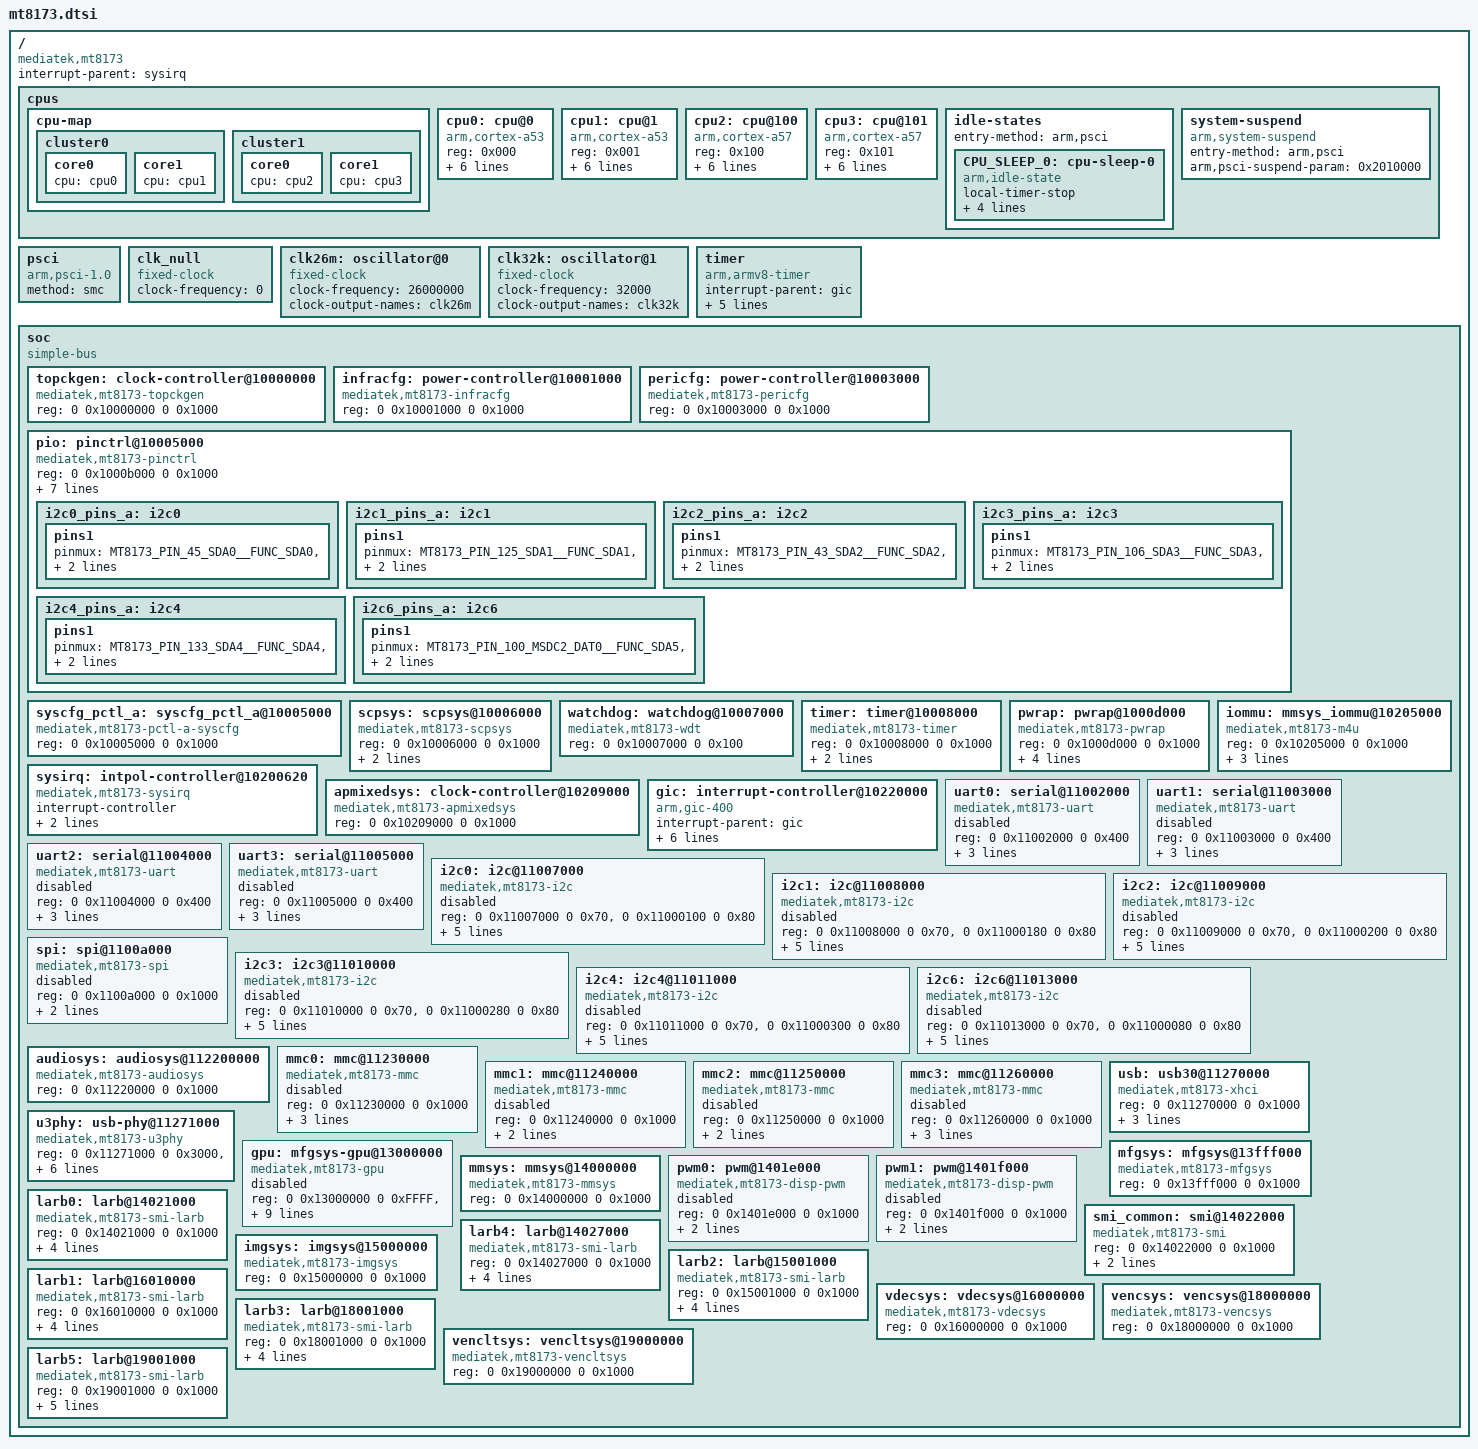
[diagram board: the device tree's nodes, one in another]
/*
 * Copyright (c) 2014 MediaTek Inc.
 * Author: Eddie Huang <eddie.huang@mediatek.com>
 *
 * This program is free software; you can redistribute it and/or modify
 * it under the terms of the GNU General Public License version 2 as
 * published by the Free Software Foundation.
 *
 * This program is distributed in the hope that it will be useful,
 * MERCHANTABILITY or FITNESS FOR A PARTICULAR PURPOSE.  See the
 * GNU General Public License for more details.
 */

#include <dt-bindings/clock/mt8173-clk.h>
#include <dt-bindings/interrupt-controller/irq.h>
#include <dt-bindings/interrupt-controller/arm-gic.h>
#include <dt-bindings/power/mt8173-power.h>
#include <dt-bindings/reset-controller/mt8173-resets.h>
#include <dt-bindings/iommu/mt8173-iommu-port.h>
#include "mt8173-pinfunc.h"

/ {
	compatible = "mediatek,mt8173";
	interrupt-parent = <&sysirq>;
	#address-cells = <2>;
	#size-cells = <2>;

	cpus {
		#address-cells = <1>;
		#size-cells = <0>;

		cpu-map {
			cluster0 {
				core0 {
					cpu = <&cpu0>;
				};
				core1 {
					cpu = <&cpu1>;
				};
			};

			cluster1 {
				core0 {
					cpu = <&cpu2>;
				};
				core1 {
					cpu = <&cpu3>;
				};
			};
		};

		cpu0: cpu@0 {
			device_type = "cpu";
			compatible = "arm,cortex-a53";
			reg = <0x000>;
			clocks = <&infracfg CLK_INFRA_CA53SEL>,
				 <&apmixedsys CLK_APMIXED_MAINPLL>;
			clock-names = "cpu", "intermediate";
			operating-points = <
				507000  859000
				702000  908000
				1001000 983000
				1105000 1009000
				1183000 1028000
				1404000 1083000
				1508000 1109000
				1573000 1125000
			>;
			enable-method = "psci";
			cpu-idle-states = <&CPU_SLEEP_0>;
		};

		cpu1: cpu@1 {
			device_type = "cpu";
			compatible = "arm,cortex-a53";
			reg = <0x001>;
			enable-method = "psci";
			clocks = <&infracfg CLK_INFRA_CA53SEL>,
				 <&apmixedsys CLK_APMIXED_MAINPLL>;
			clock-names = "cpu", "intermediate";
			operating-points = <
				507000  859000
				702000  908000
				1001000 983000
				1105000 1009000
				1183000 1028000
				1404000 1083000
				1508000 1109000
				1573000 1125000
			>;
			cpu-idle-states = <&CPU_SLEEP_0>;
		};

		cpu2: cpu@100 {
			device_type = "cpu";
			compatible = "arm,cortex-a57";
			reg = <0x100>;
			enable-method = "psci";
			clocks = <&infracfg CLK_INFRA_CA57SEL>,
				 <&apmixedsys CLK_APMIXED_MAINPLL>;
			clock-names = "cpu", "intermediate";
			operating-points = <
				507000  828000
				702000  867000
				1001000 927000
				1209000 968000
				1404000 1007000
				1612000 1049000
				1807000 1089000
				1989000 1125000
			>;
			cpu-idle-states = <&CPU_SLEEP_0>;
		};

		cpu3: cpu@101 {
			device_type = "cpu";
			compatible = "arm,cortex-a57";
			reg = <0x101>;
			enable-method = "psci";
			clocks = <&infracfg CLK_INFRA_CA57SEL>,
				 <&apmixedsys CLK_APMIXED_MAINPLL>;
			clock-names = "cpu", "intermediate";
			operating-points = <
				507000  828000
				702000  867000
				1001000 927000
				1209000 968000
				1404000 1007000
				1612000 1049000
				1807000 1089000
				1989000 1125000
			>;
			cpu-idle-states = <&CPU_SLEEP_0>;
		};

		idle-states {
			entry-method = "arm,psci";

			CPU_SLEEP_0: cpu-sleep-0 {
				compatible = "arm,idle-state";
				local-timer-stop;
				entry-latency-us = <639>;
				exit-latency-us = <680>;
				min-residency-us = <1088>;
				arm,psci-suspend-param = <0x0010000>;
			};
		};

		system-suspend {
			compatible = "arm,system-suspend";
			entry-method = "arm,psci";
			arm,psci-suspend-param = <0x2010000>;
		};


	};

	psci {
		compatible = "arm,psci-1.0";
		method = "smc";
	};

	clk_null: clk_null {
		compatible = "fixed-clock";
		clock-frequency = <0>;
		#clock-cells = <0>;
	};

	clk26m: oscillator@0 {
		compatible = "fixed-clock";
		#clock-cells = <0>;
		clock-frequency = <26000000>;
		clock-output-names = "clk26m";
	};

	clk32k: oscillator@1 {
		compatible = "fixed-clock";
		#clock-cells = <0>;
		clock-frequency = <32000>;
		clock-output-names = "clk32k";
	};

	timer {
		compatible = "arm,armv8-timer";
		interrupt-parent = <&gic>;
		interrupts = <GIC_PPI 13
			      (GIC_CPU_MASK_SIMPLE(4) | IRQ_TYPE_LEVEL_LOW)>,
			     <GIC_PPI 14
			      (GIC_CPU_MASK_SIMPLE(4) | IRQ_TYPE_LEVEL_LOW)>,
			     <GIC_PPI 11
			      (GIC_CPU_MASK_SIMPLE(4) | IRQ_TYPE_LEVEL_LOW)>,
			     <GIC_PPI 10
			      (GIC_CPU_MASK_SIMPLE(4) | IRQ_TYPE_LEVEL_LOW)>;
	};

	soc {
		#address-cells = <2>;
		#size-cells = <2>;
		compatible = "simple-bus";
		ranges;

		topckgen: clock-controller@10000000 {
			compatible = "mediatek,mt8173-topckgen";
			reg = <0 0x10000000 0 0x1000>;
			#clock-cells = <1>;
		};

		infracfg: power-controller@10001000 {
			compatible = "mediatek,mt8173-infracfg", "syscon";
			reg = <0 0x10001000 0 0x1000>;
			#clock-cells = <1>;
			#reset-cells = <1>;
		};

		pericfg: power-controller@10003000 {
			compatible = "mediatek,mt8173-pericfg", "syscon";
			reg = <0 0x10003000 0 0x1000>;
			#clock-cells = <1>;
			#reset-cells = <1>;
		};

		/*
		 * Pinctrl access register at 0x10005000 through regmap.
		 * Register 0x1000b000 is used by EINT.
		 */
		pio: pinctrl@10005000 {
			compatible = "mediatek,mt8173-pinctrl";
			reg = <0 0x1000b000 0 0x1000>;
			mediatek,pctl-regmap = <&syscfg_pctl_a>;
			pins-are-numbered;
			gpio-controller;
			#gpio-cells = <2>;
			interrupt-controller;
			#interrupt-cells = <2>;
			interrupts = <GIC_SPI 145 IRQ_TYPE_LEVEL_HIGH>,
				     <GIC_SPI 146 IRQ_TYPE_LEVEL_HIGH>,
				     <GIC_SPI 147 IRQ_TYPE_LEVEL_HIGH>;

			i2c0_pins_a: i2c0 {
				pins1 {
					pinmux = <MT8173_PIN_45_SDA0__FUNC_SDA0>,
						 <MT8173_PIN_46_SCL0__FUNC_SCL0>;
					bias-disable;
				};
			};

			i2c1_pins_a: i2c1 {
				pins1 {
					pinmux = <MT8173_PIN_125_SDA1__FUNC_SDA1>,
						 <MT8173_PIN_126_SCL1__FUNC_SCL1>;
					bias-disable;
				};
			};

			i2c2_pins_a: i2c2 {
				pins1 {
					pinmux = <MT8173_PIN_43_SDA2__FUNC_SDA2>,
						 <MT8173_PIN_44_SCL2__FUNC_SCL2>;
					bias-disable;
				};
			};

			i2c3_pins_a: i2c3 {
				pins1 {
					pinmux = <MT8173_PIN_106_SDA3__FUNC_SDA3>,
						 <MT8173_PIN_107_SCL3__FUNC_SCL3>;
					bias-disable;
				};
			};

			i2c4_pins_a: i2c4 {
				pins1 {
					pinmux = <MT8173_PIN_133_SDA4__FUNC_SDA4>,
						 <MT8173_PIN_134_SCL4__FUNC_SCL4>;
					bias-disable;
				};
			};

			i2c6_pins_a: i2c6 {
				pins1 {
					pinmux = <MT8173_PIN_100_MSDC2_DAT0__FUNC_SDA5>,
						 <MT8173_PIN_101_MSDC2_DAT1__FUNC_SCL5>;
					bias-disable;
				};
			};
		};

		syscfg_pctl_a: syscfg_pctl_a@10005000 {
			compatible = "mediatek,mt8173-pctl-a-syscfg", "syscon";
			reg = <0 0x10005000 0 0x1000>;
		};

		scpsys: scpsys@10006000 {
			compatible = "mediatek,mt8173-scpsys";
			#power-domain-cells = <1>;
			reg = <0 0x10006000 0 0x1000>;
			clocks = <&clk26m>,
				 <&topckgen CLK_TOP_MM_SEL>;
			clock-names = "mfg", "mm";
			infracfg = <&infracfg>;
		};

		watchdog: watchdog@10007000 {
			compatible = "mediatek,mt8173-wdt",
				     "mediatek,mt6589-wdt";
			reg = <0 0x10007000 0 0x100>;
		};

		timer: timer@10008000 {
			compatible = "mediatek,mt8173-timer",
				     "mediatek,mt6577-timer";
			reg = <0 0x10008000 0 0x1000>;
			interrupts = <GIC_SPI 144 IRQ_TYPE_LEVEL_LOW>;
			clock-frequency = <13000000>;
		};

		pwrap: pwrap@1000d000 {
			compatible = "mediatek,mt8173-pwrap";
			reg = <0 0x1000d000 0 0x1000>;
			reg-names = "pwrap";
			interrupts = <GIC_SPI 153 IRQ_TYPE_LEVEL_HIGH>;
			resets = <&infracfg MT8173_INFRA_PMIC_WRAP_RST>;
			reset-names = "pwrap";
			clocks = <&infracfg CLK_INFRA_PMICSPI>, <&infracfg CLK_INFRA_PMICWRAP>;
			clock-names = "spi", "wrap";
		};

		sysirq: intpol-controller@10200620 {
			compatible = "mediatek,mt8173-sysirq",
				     "mediatek,mt6577-sysirq";
			interrupt-controller;
			#interrupt-cells = <3>;
			interrupt-parent = <&gic>;
			reg = <0 0x10200620 0 0x20>;
		};

		iommu: mmsys_iommu@10205000 {
			compatible = "mediatek,mt8173-m4u";
			reg = <0 0x10205000 0 0x1000>;
			interrupts = <GIC_SPI 139 IRQ_TYPE_LEVEL_LOW>;
			clocks = <&infracfg CLK_INFRA_M4U>;
			clock-names = "bclk";
			larb = <&larb0 &larb1 &larb2 &larb3 &larb4 &larb5>;
			#iommu-cells = <2>;
		};

		apmixedsys: clock-controller@10209000 {
			compatible = "mediatek,mt8173-apmixedsys";
			reg = <0 0x10209000 0 0x1000>;
			#clock-cells = <1>;
		};

		gic: interrupt-controller@10220000 {
			compatible = "arm,gic-400";
			#interrupt-cells = <3>;
			interrupt-parent = <&gic>;
			interrupt-controller;
			reg = <0 0x10221000 0 0x1000>,
			      <0 0x10222000 0 0x2000>,
			      <0 0x10224000 0 0x2000>,
			      <0 0x10226000 0 0x2000>;
			interrupts = <GIC_PPI 9
				(GIC_CPU_MASK_SIMPLE(4) | IRQ_TYPE_LEVEL_HIGH)>;
		};

		uart0: serial@11002000 {
			compatible = "mediatek,mt8173-uart",
				     "mediatek,mt6577-uart";
			reg = <0 0x11002000 0 0x400>;
			interrupts = <GIC_SPI 83 IRQ_TYPE_LEVEL_LOW>;
			clocks = <&pericfg CLK_PERI_UART0_SEL>, <&pericfg CLK_PERI_UART0>;
			clock-names = "baud", "bus";
			status = "disabled";
		};

		uart1: serial@11003000 {
			compatible = "mediatek,mt8173-uart",
				     "mediatek,mt6577-uart";
			reg = <0 0x11003000 0 0x400>;
			interrupts = <GIC_SPI 84 IRQ_TYPE_LEVEL_LOW>;
			clocks = <&pericfg CLK_PERI_UART1_SEL>, <&pericfg CLK_PERI_UART1>;
			clock-names = "baud", "bus";
			status = "disabled";
		};

		uart2: serial@11004000 {
			compatible = "mediatek,mt8173-uart",
				     "mediatek,mt6577-uart";
			reg = <0 0x11004000 0 0x400>;
			interrupts = <GIC_SPI 85 IRQ_TYPE_LEVEL_LOW>;
			clocks = <&pericfg CLK_PERI_UART2_SEL>, <&pericfg CLK_PERI_UART2>;
			clock-names = "baud", "bus";
			status = "disabled";
		};

		uart3: serial@11005000 {
			compatible = "mediatek,mt8173-uart",
				     "mediatek,mt6577-uart";
			reg = <0 0x11005000 0 0x400>;
			interrupts = <GIC_SPI 86 IRQ_TYPE_LEVEL_LOW>;
			clocks = <&pericfg CLK_PERI_UART3_SEL>, <&pericfg CLK_PERI_UART3>;
			clock-names = "baud", "bus";
			status = "disabled";
		};

		i2c0: i2c@11007000 {
			compatible = "mediatek,mt8173-i2c";
			reg = <0 0x11007000 0 0x70>,
			      <0 0x11000100 0 0x80>;
			interrupts = <GIC_SPI 76 IRQ_TYPE_LEVEL_LOW>;
			clock-div = <16>;
			clocks = <&pericfg CLK_PERI_I2C0>,
				 <&pericfg CLK_PERI_AP_DMA>;
			clock-names = "main", "dma";
			pinctrl-names = "default";
			pinctrl-0 = <&i2c0_pins_a>;
			#address-cells = <1>;
			#size-cells = <0>;
			status = "disabled";
		};

		i2c1: i2c@11008000 {
			compatible = "mediatek,mt8173-i2c";
			reg = <0 0x11008000 0 0x70>,
			      <0 0x11000180 0 0x80>;
			interrupts = <GIC_SPI 77 IRQ_TYPE_LEVEL_LOW>;
			clock-div = <16>;
			clocks = <&pericfg CLK_PERI_I2C1>,
				 <&pericfg CLK_PERI_AP_DMA>;
			clock-names = "main", "dma";
			pinctrl-names = "default";
			pinctrl-0 = <&i2c1_pins_a>;
			#address-cells = <1>;
			#size-cells = <0>;
			status = "disabled";
		};

		i2c2: i2c@11009000 {
			compatible = "mediatek,mt8173-i2c";
			reg = <0 0x11009000 0 0x70>,
			      <0 0x11000200 0 0x80>;
			interrupts = <GIC_SPI 78 IRQ_TYPE_LEVEL_LOW>;
			clock-div = <16>;
			clocks = <&pericfg CLK_PERI_I2C2>,
				 <&pericfg CLK_PERI_AP_DMA>;
			clock-names = "main", "dma";
			pinctrl-names = "default";
			pinctrl-0 = <&i2c2_pins_a>;
			#address-cells = <1>;
			#size-cells = <0>;
			status = "disabled";
		};

		spi: spi@1100a000 {
			compatible = "mediatek,mt8173-spi";
			reg = <0 0x1100a000 0 0x1000>;
			interrupts = <GIC_SPI 110 IRQ_TYPE_LEVEL_LOW>;
			clocks = <&pericfg CLK_PERI_SPI0>;
			clock-names = "main";
			status = "disabled";
		};

		i2c3: i2c3@11010000 {
			compatible = "mediatek,mt8173-i2c";
			reg = <0 0x11010000 0 0x70>,
			      <0 0x11000280 0 0x80>;
			interrupts = <GIC_SPI 79 IRQ_TYPE_LEVEL_LOW>;
			clock-div = <16>;
			clocks = <&pericfg CLK_PERI_I2C3>,
				 <&pericfg CLK_PERI_AP_DMA>;
			clock-names = "main", "dma";
			pinctrl-names = "default";
			pinctrl-0 = <&i2c3_pins_a>;
			#address-cells = <1>;
			#size-cells = <0>;
			status = "disabled";
		};

		i2c4: i2c4@11011000 {
			compatible = "mediatek,mt8173-i2c";
			reg = <0 0x11011000 0 0x70>,
			      <0 0x11000300 0 0x80>;
			interrupts = <GIC_SPI 80 IRQ_TYPE_LEVEL_LOW>;
			clock-div = <16>;
			clocks = <&pericfg CLK_PERI_I2C4>,
				 <&pericfg CLK_PERI_AP_DMA>;
			clock-names = "main", "dma";
			pinctrl-names = "default";
			pinctrl-0 = <&i2c4_pins_a>;
			#address-cells = <1>;
			#size-cells = <0>;
			status = "disabled";
		};

		i2c6: i2c6@11013000 {
			compatible = "mediatek,mt8173-i2c";
			reg = <0 0x11013000 0 0x70>,
			      <0 0x11000080 0 0x80>;
			interrupts = <GIC_SPI 82 IRQ_TYPE_LEVEL_LOW>;
			clock-div = <16>;
			clocks = <&pericfg CLK_PERI_I2C6>,
				 <&pericfg CLK_PERI_AP_DMA>;
			clock-names = "main", "dma";
			pinctrl-names = "default";
			pinctrl-0 = <&i2c6_pins_a>;
			#address-cells = <1>;
			#size-cells = <0>;
			status = "disabled";
		};

		audiosys: audiosys@112200000 {
			compatible = "mediatek,mt8173-audiosys", "syscon";
			reg = <0 0x11220000 0 0x1000>;
			#clock-cells = <1>;
		};

		mmc0: mmc@11230000 {
			compatible = "mediatek,mt8173-mmc",
				     "mediatek,mt8135-mmc";
			reg = <0 0x11230000 0 0x1000>;
			interrupts = <GIC_SPI 71 IRQ_TYPE_LEVEL_LOW>;
			clocks = <&pericfg CLK_PERI_MSDC30_0>,
				 <&topckgen CLK_TOP_MSDC50_0_H_SEL>;
			clock-names = "source", "hclk";
			status = "disabled";
		};

		mmc1: mmc@11240000 {
			compatible = "mediatek,mt8173-mmc",
				     "mediatek,mt8135-mmc";
			reg = <0 0x11240000 0 0x1000>;
			interrupts = <GIC_SPI 72 IRQ_TYPE_LEVEL_LOW>;
			clocks = <&pericfg CLK_PERI_MSDC30_1>,
				 <&clk_null>;
			clock-names = "source", "hclk";
			status = "disabled";
		};

		mmc2: mmc@11250000 {
			compatible = "mediatek,mt8173-mmc",
				     "mediatek,mt8135-mmc";
			reg = <0 0x11250000 0 0x1000>;
			interrupts = <GIC_SPI 73 IRQ_TYPE_LEVEL_LOW>;
			clocks = <&pericfg CLK_PERI_MSDC30_2>,
				 <&clk_null>;
			clock-names = "source", "hclk";
			status = "disabled";
		};

		mmc3: mmc@11260000 {
			compatible = "mediatek,mt8173-mmc",
				     "mediatek,mt8135-mmc";
			reg = <0 0x11260000 0 0x1000>;
			interrupts = <GIC_SPI 74 IRQ_TYPE_LEVEL_LOW>;
			clocks = <&pericfg CLK_PERI_MSDC30_3>,
				 <&topckgen CLK_TOP_MSDC50_2_H_SEL>;
			clock-names = "source", "hclk";
			status = "disabled";
		};

		usb: usb30@11270000 {
			compatible = "mediatek,mt8173-xhci", "generic-xhci";
			reg = <0 0x11270000 0 0x1000>;
			interrupts = <GIC_SPI 115 IRQ_TYPE_LEVEL_LOW>;
			usb-phy = <&u3phy>;
			usb3-lpm-capable;
		};

		u3phy: usb-phy@11271000 {
			compatible = "mediatek,mt8173-u3phy";
			reg = <0 0x11271000 0 0x3000>,
			      <0 0x11280000 0 0x20000>;
			power-domains = <&scpsys MT8173_POWER_DOMAIN_USB>;
			clocks = <&pericfg CLK_PERI_USB0>,
				 <&pericfg CLK_PERI_USB1>,
				 <&topckgen CLK_TOP_USB30_SEL>,
				 <&apmixedsys CLK_APMIXED_REF2USB_TX>;
			clock-names = "wakeup_deb_p0",
				      "wakeup_deb_p1",
				      "sys_mac",
				      "u3phya_ref";
		};

		gpu: mfgsys-gpu@13000000 {
			compatible = "mediatek,mt8173-gpu";
			reg = <0 0x13000000 0 0xFFFF>, <0 0x13fff000 0 0x1000>;
			power-domains =	<&scpsys MT8173_POWER_DOMAIN_MFG>;
			clocks = <&apmixedsys CLK_APMIXED_MMPLL>,
				 <&topckgen CLK_TOP_MEM_MFG_IN_SEL>,
				 <&topckgen CLK_TOP_AXI_MFG_IN_SEL>,
				 <&topckgen CLK_TOP_AXI_SEL>,
				 <&topckgen CLK_TOP_MEM_SEL>,
				 <&topckgen CLK_TOP_MFG_SEL>;

			clock-names = "mmpll_clk",
				      "mfg_mem_in_sel",
				      "mfg_axi_in_sel",
				      "top_axi",
				      "top_mem",
				      "top_mfg";

			interrupts = <0 217 IRQ_TYPE_LEVEL_LOW>;
			interrupt-names = "RGX";
			status = "disabled";
		};

		mfgsys: mfgsys@13fff000 {
			compatible = "mediatek,mt8173-mfgsys", "syscon";
			reg = <0 0x13fff000 0 0x1000>;
			#clock-cells = <1>;
		};

		mmsys: mmsys@14000000 {
			compatible = "mediatek,mt8173-mmsys", "syscon";
			reg = <0 0x14000000 0 0x1000>;
			#clock-cells = <1>;
		};

		pwm0: pwm@1401e000 {
			compatible = "mediatek,mt8173-disp-pwm",
				     "mediatek,mt6595-disp-pwm";
			reg = <0 0x1401e000 0 0x1000>;
			#pwm-cells = <2>;
			clocks = <&mmsys CLK_MM_DISP_PWM026M>,
				 <&mmsys CLK_MM_DISP_PWM0MM>;
			clock-names = "main", "mm";
			status = "disabled";
		};

		pwm1: pwm@1401f000 {
			compatible = "mediatek,mt8173-disp-pwm",
				     "mediatek,mt6595-disp-pwm";
			reg = <0 0x1401f000 0 0x1000>;
			#pwm-cells = <2>;
			clocks = <&mmsys CLK_MM_DISP_PWM126M>,
				 <&mmsys CLK_MM_DISP_PWM1MM>;
			clock-names = "main", "mm";
			status = "disabled";
		};

		larb0:larb@14021000 {
			compatible = "mediatek,mt8173-smi-larb";
			reg = <0 0x14021000 0 0x1000>;
			smi = <&smi_common>;
			power-domains = <&scpsys MT8173_POWER_DOMAIN_MM>;
			clocks = <&mmsys CLK_MM_SMI_LARB0>,
				 <&mmsys CLK_MM_SMI_LARB0>;
			clock-names = "apb", "smi";
		};

		smi_common:smi@14022000 {
			compatible = "mediatek,mt8173-smi";
			reg = <0 0x14022000 0 0x1000>;
			clocks = <&mmsys CLK_MM_SMI_COMMON>,
				 <&mmsys CLK_MM_SMI_COMMON>;
			clock-names = "apb", "smi";
		};

		larb4:larb@14027000 {
			compatible = "mediatek,mt8173-smi-larb";
			reg = <0 0x14027000 0 0x1000>;
			smi = <&smi_common>;
			power-domains = <&scpsys MT8173_POWER_DOMAIN_MM>;
			clocks = <&mmsys CLK_MM_SMI_LARB4>,
				 <&mmsys CLK_MM_SMI_LARB4>;
			clock-names = "apb", "smi";
		};

		imgsys: imgsys@15000000 {
			compatible = "mediatek,mt8173-imgsys", "syscon";
			reg = <0 0x15000000 0 0x1000>;
			#clock-cells = <1>;
		};

		larb2:larb@15001000 {
			compatible = "mediatek,mt8173-smi-larb";
			reg = <0 0x15001000 0 0x1000>;
			smi = <&smi_common>;
			power-domains = <&scpsys MT8173_POWER_DOMAIN_ISP>;
			clocks = <&imgsys CLK_IMG_LARB2_SMI>,
				 <&imgsys CLK_IMG_LARB2_SMI>;
			clock-names = "apb", "smi";
		};

		vdecsys: vdecsys@16000000 {
			compatible = "mediatek,mt8173-vdecsys", "syscon";
			reg = <0 0x16000000 0 0x1000>;
			#clock-cells = <1>;
		};

		larb1:larb@16010000 {
			compatible = "mediatek,mt8173-smi-larb";
			reg = <0 0x16010000 0 0x1000>;
			smi = <&smi_common>;
			power-domains = <&scpsys MT8173_POWER_DOMAIN_VDEC>;
			clocks = <&vdecsys CLK_VDEC_CKEN>,
				 <&vdecsys CLK_VDEC_LARB_CKEN>;
			clock-names = "apb", "smi";
		};


		vencsys: vencsys@18000000 {
			compatible = "mediatek,mt8173-vencsys", "syscon";
			reg = <0 0x18000000 0 0x1000>;
			#clock-cells = <1>;
		};

		larb3:larb@18001000 {
			compatible = "mediatek,mt8173-smi-larb";
			reg = <0 0x18001000 0 0x1000>;
			smi = <&smi_common>;
			power-domains = <&scpsys MT8173_POWER_DOMAIN_VENC>;
			clocks = <&vencsys CLK_VENC_CKE1>,
				 <&vencsys CLK_VENC_CKE0>;
			clock-names = "apb", "smi";
		};

		vencltsys: vencltsys@19000000 {
			compatible = "mediatek,mt8173-vencltsys", "syscon";
			reg = <0 0x19000000 0 0x1000>;
			#clock-cells = <1>;
		};

		larb5:larb@19001000 {
			compatible = "mediatek,mt8173-smi-larb";
			reg = <0 0x19001000 0 0x1000>;
			smi = <&smi_common>;
			power-domains = <&scpsys MT8173_POWER_DOMAIN_VENC_LT>;
			clocks = <&vencltsys CLK_VENCLT_CKE1>,
				 <&vencltsys CLK_VENCLT_CKE0>;
			clock-names = "apb", "smi";
		};
	};
};

